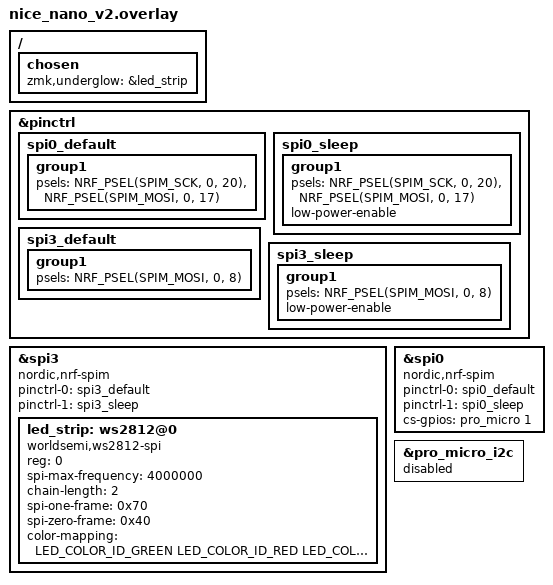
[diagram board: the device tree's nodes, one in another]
#include <dt-bindings/led/led.h>

/ {
    chosen {
        zmk,underglow = &led_strip;
    };
};


//	sck= SCL
//	mosi= SDA
&pinctrl {
    spi0_default: spi0_default {
        group1 {
            psels = <NRF_PSEL(SPIM_SCK, 0, 20)>,    //P3 (SCL)
                    <NRF_PSEL(SPIM_MOSI, 0, 17)>;   //P2 (SDA)
        };
    };
    spi0_sleep: spi0_sleep {
        group1 {
            psels = <NRF_PSEL(SPIM_SCK, 0, 20)>,    //P3 (SCL)
                    <NRF_PSEL(SPIM_MOSI, 0, 17)>;   //P2 (SDA)
            low-power-enable;
        };
    };
    spi3_default: spi3_default {
        group1 {
            psels = <NRF_PSEL(SPIM_MOSI, 0, 8)>;
        };
    };

    spi3_sleep: spi3_sleep {
        group1 {
            psels = <NRF_PSEL(SPIM_MOSI, 0, 8)>;
            low-power-enable;
        };
    };
};


&spi3 {
    compatible = "nordic,nrf-spim";
    status = "okay";

    pinctrl-0 = <&spi3_default>;
    pinctrl-1 = <&spi3_sleep>;
    pinctrl-names = "default", "sleep";

    led_strip: ws2812@0 {
        compatible = "worldsemi,ws2812-spi";

        /* SPI */
        reg = <0>; /* ignored, but necessary for SPI bindings */
        spi-max-frequency = <4000000>;

        /* WS2812 */
        chain-length = <2>; /* number of LEDs */
        spi-one-frame = <0x70>;
        spi-zero-frame = <0x40>;
        color-mapping = <LED_COLOR_ID_GREEN
                         LED_COLOR_ID_RED
                         LED_COLOR_ID_BLUE>;
    };
};

nice_view_spi: &spi0 {
    compatible = "nordic,nrf-spim";
    pinctrl-0 = <&spi0_default>;
    pinctrl-1 = <&spi0_sleep>;
    pinctrl-names = "default", "sleep";
    cs-gpios = <&pro_micro 1 GPIO_ACTIVE_HIGH>; //P1 (CS)
};

&pro_micro_i2c {
    status = "disabled";
};
